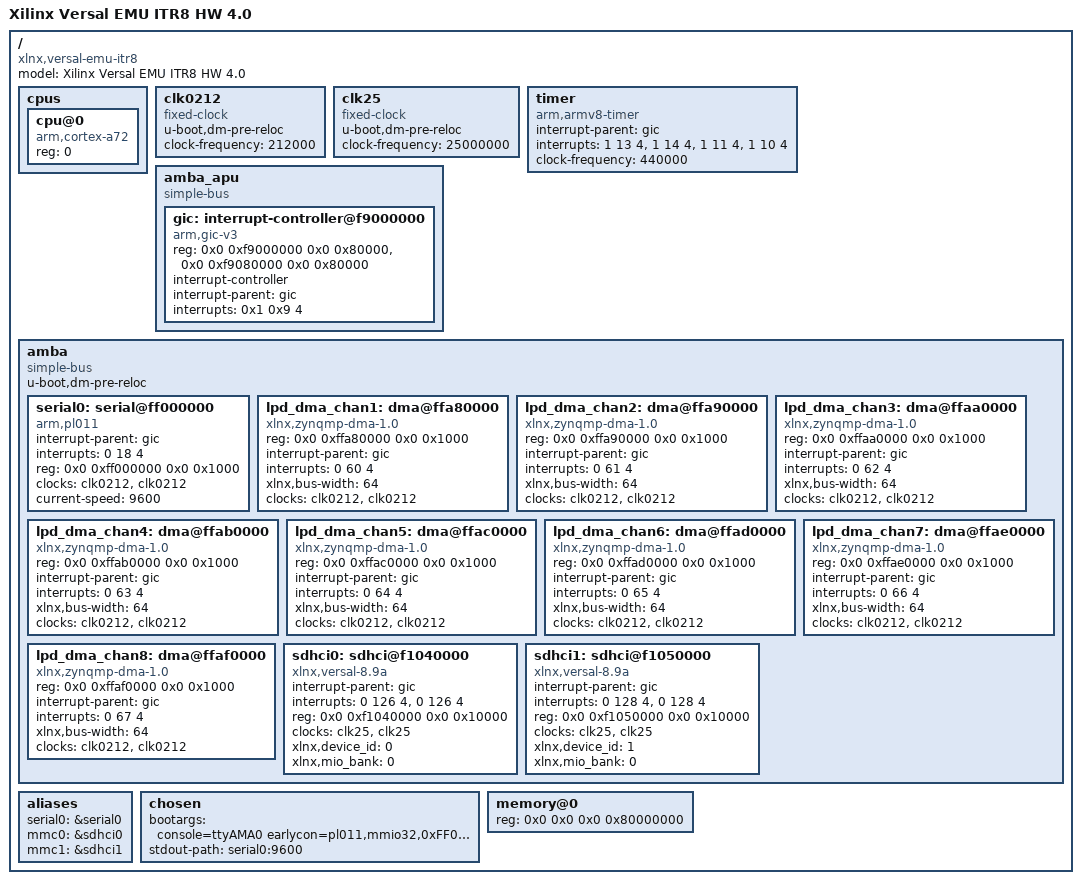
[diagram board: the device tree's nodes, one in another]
/ {
	compatible = "xlnx,versal-emu-itr8", "xlnx,versal-emu", "xlnx,versal";
	#address-cells = <2>;
	#size-cells = <2>;
	model = "Xilinx Versal EMU ITR8 HW 4.0";

	cpus {
		#address-cells = <1>;
		#size-cells = <0>;

		cpu@0 {
			compatible = "arm,cortex-a72", "arm,armv8";
			device_type = "cpu";
			reg = <0>;
		};
	};

	clk0212: clk0212 {
		u-boot,dm-pre-reloc;
		compatible = "fixed-clock";
		#clock-cells = <0x0>;
		clock-frequency = <212000>;
	};

	clk25: clk25 {
		u-boot,dm-pre-reloc;
		compatible = "fixed-clock";
		#clock-cells = <0x0>;
		clock-frequency = <25000000>;
	};

	timer {
		compatible = "arm,armv8-timer";
		interrupt-parent = <&gic>;
		interrupts = <1 13 4>,
			     <1 14 4>,
			     <1 11 4>,
			     <1 10 4>;
		clock-frequency = <440000>;
	};

	amba_apu: amba_apu {
		compatible = "simple-bus";
		#address-cells = <2>;
		#size-cells = <2>;
		ranges;

		gic: interrupt-controller@f9000000 {
			compatible = "arm,gic-v3";
			#interrupt-cells = <3>;
			reg = <0x0 0xf9000000 0x0 0x80000>, /* GICD */
			      <0x0 0xf9080000 0x0 0x80000>; /* GICR */
			interrupt-controller;
			interrupt-parent = <&gic>;
			interrupts = <0x1 0x9 4>;
		};
	};

	amba: amba {
		u-boot,dm-pre-reloc;
		compatible = "simple-bus";
		#address-cells = <0x2>;
		#size-cells = <0x2>;
		ranges;

		serial0: serial@ff000000 {
			compatible = "arm,pl011", "arm,sbsa-uart";
			status = "okay";
			interrupt-parent = <&gic>;
			interrupts = <0 18 4>;
			reg = <0x0 0xff000000 0x0 0x1000>;
			clock-names = "uart_clk", "apb_clk";
			clocks = <&clk0212 &clk0212>;
			current-speed = <9600>;
		};

		lpd_dma_chan1: dma@ffa80000 {
			status = "okay";
			compatible = "xlnx,zynqmp-dma-1.0";
			clock-names = "clk_main", "clk_apb";
			reg = <0x0 0xffa80000 0x0 0x1000>;
			interrupt-parent = <&gic>;
			interrupts = <0 60 4>;
			xlnx,bus-width = <64>;
			clocks = <&clk0212 &clk0212>;
		};

		lpd_dma_chan2: dma@ffa90000 {
			status = "okay";
			compatible = "xlnx,zynqmp-dma-1.0";
			clock-names = "clk_main", "clk_apb";
			reg = <0x0 0xffa90000 0x0 0x1000>;
			interrupt-parent = <&gic>;
			interrupts = <0 61 4>;
			xlnx,bus-width = <64>;
			clocks = <&clk0212 &clk0212>;
		};

		lpd_dma_chan3: dma@ffaa0000 {
			status = "okay";
			compatible = "xlnx,zynqmp-dma-1.0";
			clock-names = "clk_main", "clk_apb";
			reg = <0x0 0xffaa0000 0x0 0x1000>;
			interrupt-parent = <&gic>;
			interrupts = <0 62 4>;
			xlnx,bus-width = <64>;
			clocks = <&clk0212 &clk0212>;
		};

		lpd_dma_chan4: dma@ffab0000 {
			status = "okay";
			compatible = "xlnx,zynqmp-dma-1.0";
			clock-names = "clk_main", "clk_apb";
			reg = <0x0 0xffab0000 0x0 0x1000>;
			interrupt-parent = <&gic>;
			interrupts = <0 63 4>;
			xlnx,bus-width = <64>;
			clocks = <&clk0212 &clk0212>;
		};

		lpd_dma_chan5: dma@ffac0000 {
			status = "okay";
			compatible = "xlnx,zynqmp-dma-1.0";
			clock-names = "clk_main", "clk_apb";
			reg = <0x0 0xffac0000 0x0 0x1000>;
			interrupt-parent = <&gic>;
			interrupts = <0 64 4>;
			xlnx,bus-width = <64>;
			clocks = <&clk0212 &clk0212>;
		};

		lpd_dma_chan6: dma@ffad0000 {
			status = "okay";
			compatible = "xlnx,zynqmp-dma-1.0";
			clock-names = "clk_main", "clk_apb";
			reg = <0x0 0xffad0000 0x0 0x1000>;
			interrupt-parent = <&gic>;
			interrupts = <0 65 4>;
			xlnx,bus-width = <64>;
			clocks = <&clk0212 &clk0212>;
		};

		lpd_dma_chan7: dma@ffae0000 {
			status = "okay";
			compatible = "xlnx,zynqmp-dma-1.0";
			clock-names = "clk_main", "clk_apb";
			reg = <0x0 0xffae0000 0x0 0x1000>;
			interrupt-parent = <&gic>;
			interrupts = <0 66 4>;
			xlnx,bus-width = <64>;
			clocks = <&clk0212 &clk0212>;
		};

		lpd_dma_chan8: dma@ffaf0000 {
			status = "okay";
			compatible = "xlnx,zynqmp-dma-1.0";
			clock-names = "clk_main", "clk_apb";
			reg = <0x0 0xffaf0000 0x0 0x1000>;
			interrupt-parent = <&gic>;
			interrupts = <0 67 4>;
			xlnx,bus-width = <64>;
			clocks = <&clk0212 &clk0212>;
		};

		sdhci0: sdhci@f1040000 {
			compatible = "xlnx,versal-8.9a", "arasan,sdhci-8.9a";
			status = "okay";
			interrupt-parent = <&gic>;
			interrupts = <0 126 4>, <0 126 4>;
			reg = <0x0 0xf1040000 0x0 0x10000>;
			clock-names = "clk_xin", "clk_ahb";
			clocks = <&clk25 &clk25>;
			xlnx,device_id = <0>;
			xlnx,mio_bank = <0>;
			#stream-id-cells = <1>;
		};

		sdhci1: sdhci@f1050000 {
			compatible = "xlnx,versal-8.9a", "arasan,sdhci-8.9a";
			status = "okay";
			interrupt-parent = <&gic>;
			interrupts = <0 128 4>, <0 128 4>;
			reg = <0x0 0xf1050000 0x0 0x10000>;
			clock-names = "clk_xin", "clk_ahb";
			clocks = <&clk25 &clk25>;
			xlnx,device_id = <1>;
			xlnx,mio_bank = <0>;
			#stream-id-cells = <1>;
		};
	};

	aliases {
		serial0 = &serial0;
		mmc0 = &sdhci0;
		mmc1 = &sdhci1;
	};

	chosen {
		bootargs = "console=ttyAMA0 earlycon=pl011,mmio32,0xFF000000,9600n8 clk_ignore_unused maxcpus=1";
		stdout-path = "serial0:9600";
	};

	memory@0 {
		device_type = "memory";
		reg = <0x0 0x0 0x0 0x80000000>;
	};
};
